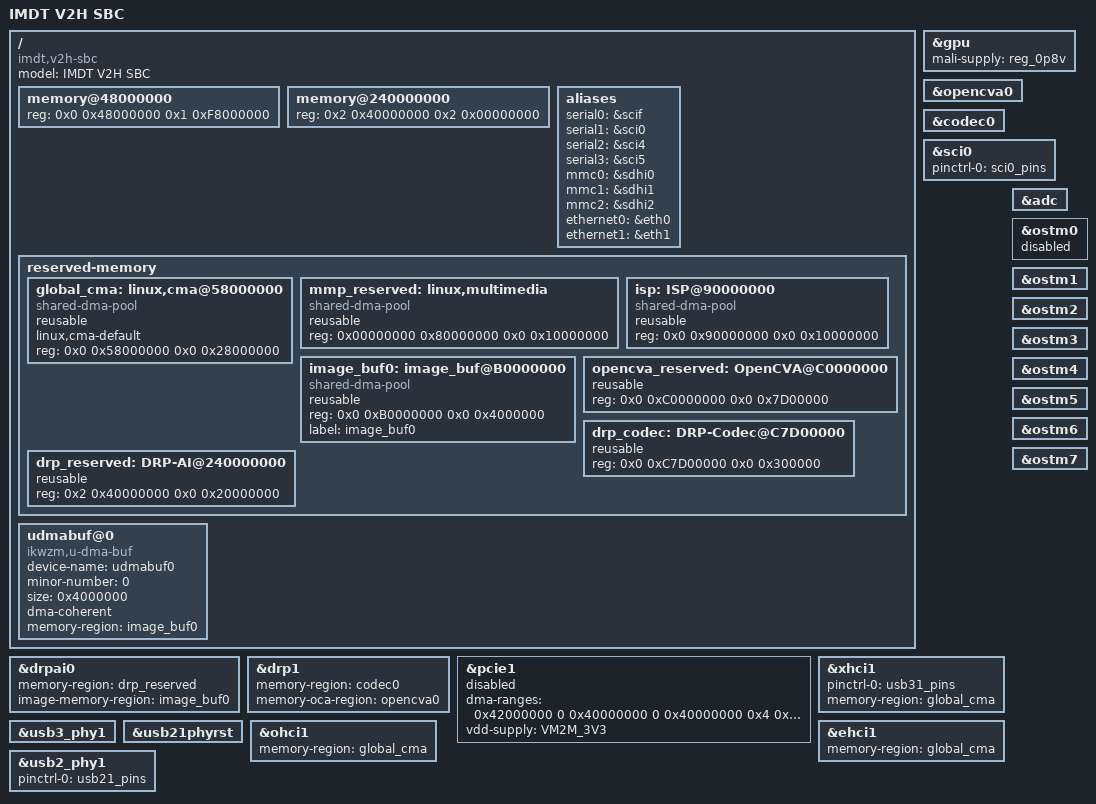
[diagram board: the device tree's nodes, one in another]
// SPDX-License-Identifier: (GPL-2.0-only OR BSD-2-Clause)
/*
* Device Tree Source for the IMDT-V2H SBC
*
* Copyright (C) 2026 Renesas Electronics Corp.
*/

/dts-v1/;
#include "r9a09g057.dtsi"
#include "r9a09g057-multi-os.dtsi"
#include <dt-bindings/pinctrl/rzv2h-pinctrl.h>
#include <dt-bindings/gpio/gpio.h>
#include "imdt-v2-sbc.dtsi"

/ {
	model = "IMDT V2H SBC";
	compatible = "imdt,v2h-sbc", "renesas,r9a09g057h4", "renesas,r9a09g057";

	memory@48000000 {
		device_type = "memory";
		/* first 128MB is reserved for secure area. */
		reg = <0x0 0x48000000 0x1 0xF8000000>;
	};

	memory@240000000 {
		device_type = "memory";
		reg = <0x2 0x40000000 0x2 0x00000000>;
	};
	
	aliases {
		serial0 = &scif;
		serial1 = &sci0;
		serial2 = &sci4;
		serial3 = &sci5;
		mmc0 = &sdhi0;
		mmc1 = &sdhi1;
		mmc2 = &sdhi2;
		ethernet0 = &eth0;
		ethernet1 = &eth1;
	};

	reserved-memory {
		#address-cells = <2>;
		#size-cells = <2>;
		ranges;
		global_cma: linux,cma@58000000 {
			compatible = "shared-dma-pool";
			reusable;
			linux,cma-default;
			reg = <0x0 0x58000000 0x0 0x28000000>;
		};

		mmp_reserved: linux,multimedia {
			compatible = "shared-dma-pool";
			reusable;
			reg = <0x00000000 0x80000000 0x0 0x10000000>;
		};

		isp: ISP@90000000 {
			compatible = "shared-dma-pool";
			reusable;
			reg = <0x0 0x90000000 0x0 0x10000000>;
		};

		image_buf0: image_buf@B0000000 {
			compatible = "shared-dma-pool";
			reusable;
			reg = <0x0 0xB0000000 0x0 0x4000000>;
			label = "image_buf0";
		};

		opencva_reserved: OpenCVA@C0000000 {
			reusable;
			reg = <0x0 0xC0000000 0x0 0x7D00000>;
		};

		drp_codec: DRP-Codec@C7D00000 {
			reusable;
			reg = <0x0 0xC7D00000 0x0 0x300000>;
		};

		drp_reserved: DRP-AI@240000000 {
			reusable;
			reg = <0x2 0x40000000 0x0 0x20000000>;
		};
	};

	udmabuf@0 {
			compatible = "ikwzm,u-dma-buf";
			device-name = "udmabuf0";
			minor-number = <0>;
			size = <0x4000000>; // 64MiB
			dma-coherent;
			memory-region = <&image_buf0>;
	};
};

&gpu {
	status = "okay";
	mali-supply = <&reg_0p8v>;
};

&opencva0{
	status = "okay";
};

&codec0 {
	status = "okay";
};

&drpai0 {
	memory-region = <&drp_reserved>;
	image-memory-region = <&image_buf0>;
	status = "okay";
};

&drp1 {
	memory-region = <&codec0>;
	memory-oca-region = <&opencva0>;

	status = "okay";
};

&sci0 {
	pinctrl-0 = <&sci0_pins>;
	pinctrl-names = "default";
	status = "okay";
};

&pcie1 {
	/* Map all possible DDR as inbound ranges */
	ranges = <0x03000000 0x0 0x38000000 0x0 0x38000000 0x0 0x08000000>;
	dma-ranges = <0x42000000 0 0x40000000 0 0x40000000 0x4 0x00000000>;
	vdd-supply = <&VM2M_3V3>;
	status = "disabled"; //checking for shared pcie
};

&xhci1 {
	pinctrl-0 = <&usb31_pins>;
	pinctrl-names = "default";

	memory-region = <&global_cma>;
	status = "okay";
};

/*
 * USB3 PHY for xhci1. The board enables xhci1 but the SoC leaves this PHY
 * disabled by default; xhci1 references it via phys = <&usb3_phy1>, so without
 * it the controller can't acquire a PHY and never finishes probing (no xHCI
 * root hub appears at all). Enable it so devices on this channel - including
 * the M.2 Key-E USB (Bluetooth) - can enumerate.
 */
&usb3_phy1 {
	status = "okay";
};

&usb21phyrst {
	status = "okay";
};

&ohci1 {
	memory-region = <&global_cma>;

	status = "okay";
};

&ehci1 {
	memory-region = <&global_cma>;

	status = "okay";
};

&usb2_phy1 {
	pinctrl-0 = <&usb21_pins>;
	pinctrl-names = "default";

	status = "okay";
};

&adc {
	status = "okay";
};

&ostm0 {
	status = "disabled";
};

&ostm1 {
	status = "okay";
};

&ostm2 {
	status = "okay";
};

&ostm3 {
	status = "okay";
};

&ostm4 {
	status = "okay";
};

&ostm5 {
	status = "okay";
};

&ostm6 {
	status = "okay";
};

&ostm7 {
	status = "okay";
};
